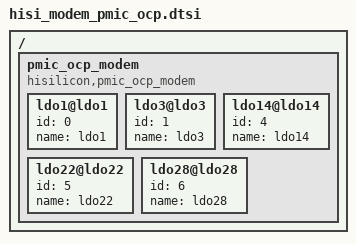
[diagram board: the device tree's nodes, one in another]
/*
 * Hisilicon Ltd Balong SOC
 */

/include/ "skeleton.dtsi"

/{
    pmic_ocp_modem {   
        compatible = "hisilicon,pmic_ocp_modem";
        status = "ok";    

        ldo1@ldo1{
            id = <0>;
            name = "ldo1";
        };
        ldo3@ldo3{
            id = <1>;
            name = "ldo3";
        };
        ldo14@ldo14{
            id = <4>;
            name = "ldo14";
        };
        ldo22@ldo22{
            id = <5>;
            name = "ldo22";
        };
        ldo28@ldo28{
            id = <6>;
            name = "ldo28";
        };
    };
};
